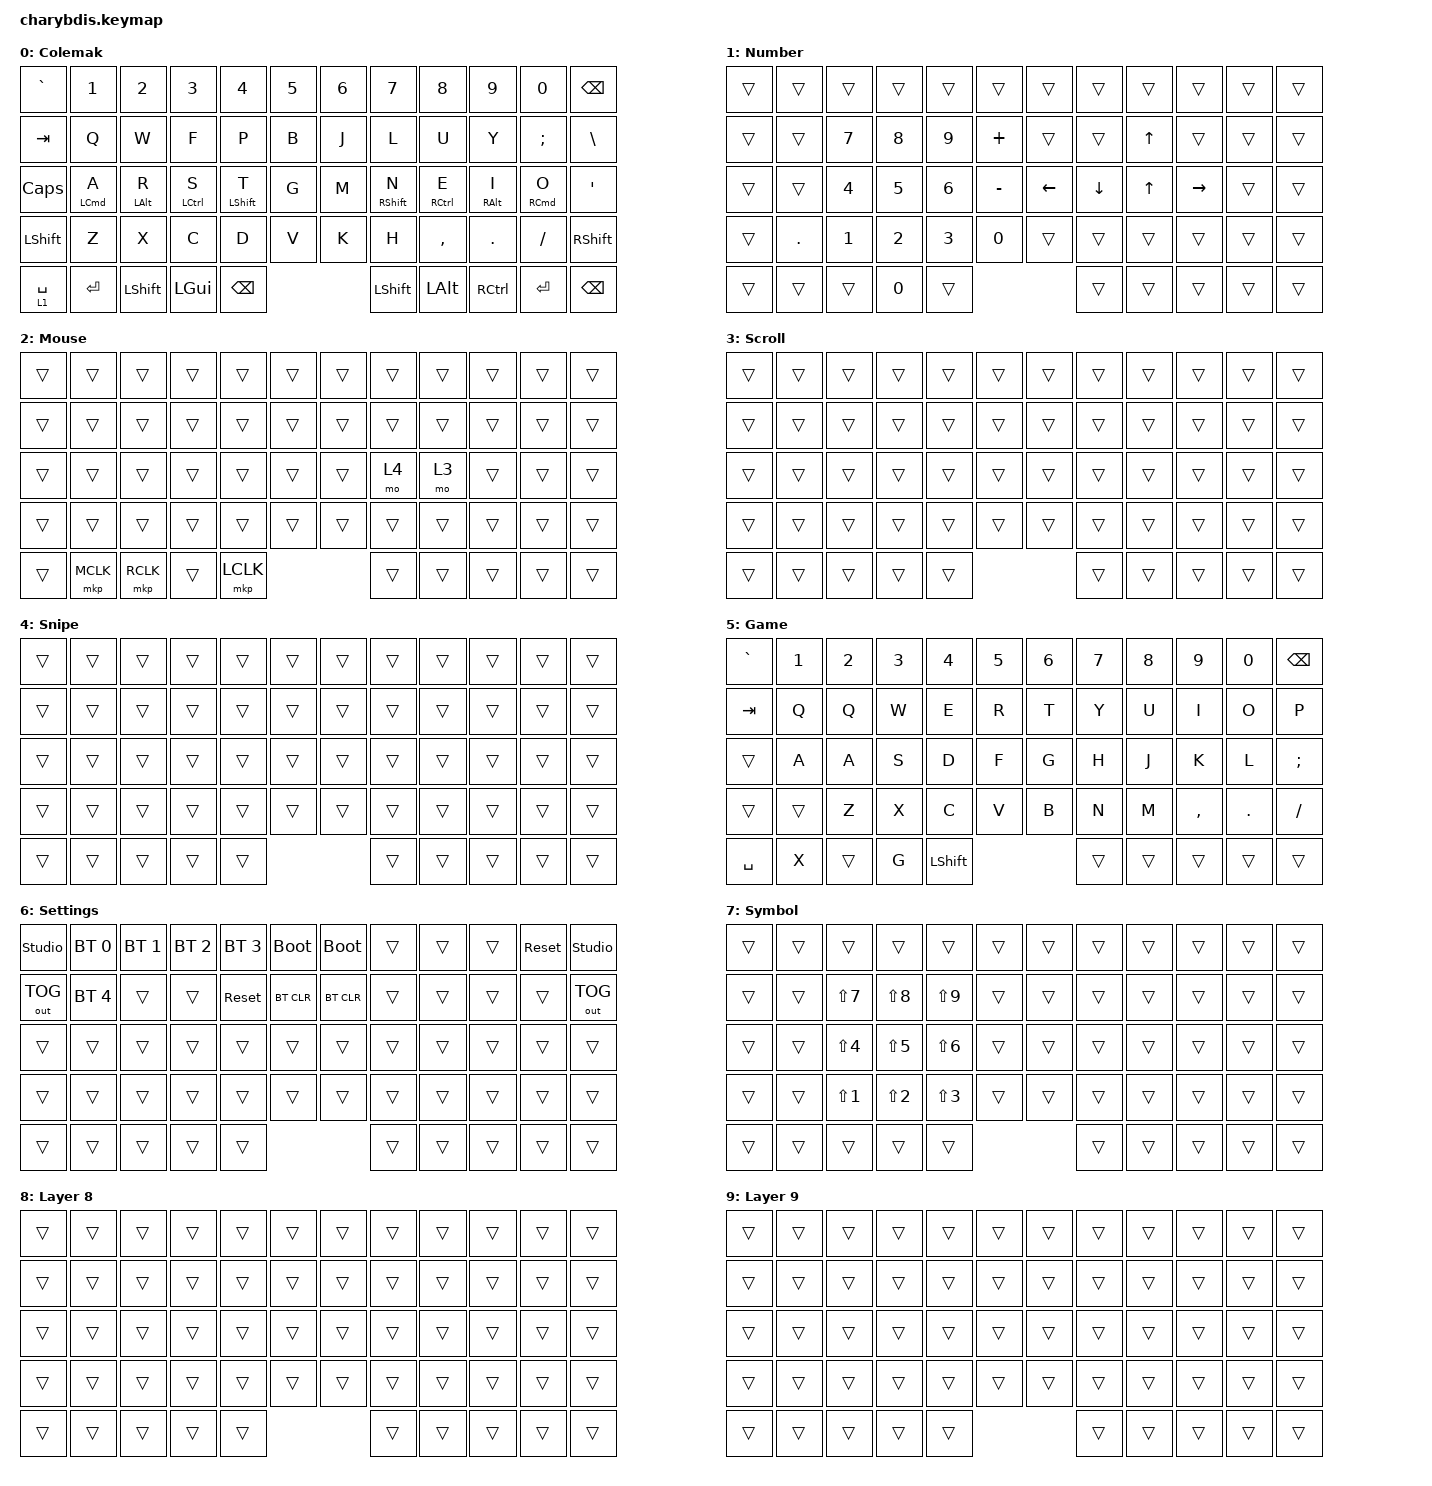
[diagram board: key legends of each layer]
#ifndef ZMK_BEHAVIORS_KEEP_ALL
#define ZMK_BEHAVIORS_KEEP_ALL
#endif
#include <behaviors.dtsi>
#include <behaviors/runtime_macro.dtsi>
#include <dt-bindings/zmk/bt.h>
#include <dt-bindings/zmk/ext_power.h>
#include <dt-bindings/zmk/keys.h>
#include <dt-bindings/zmk/outputs.h>
#include <dt-bindings/zmk/pointing.h>
#include <dt-bindings/input/input-event-codes.h>

/ {
    behaviors {
        hml: homewrow_mods_left {
            compatible = "zmk,behavior-hold-tap";
            bindings = <&kp>, <&kp>;

            #binding-cells = <2>;
            hold-trigger-key-positions = <6 7 8 9 10 11 18 19 20 21 22 23 30 31 32 33 34 35 42 43 44 45 46 47 53 54 55 56 57>;
            tapping-term-ms = <300>;
            flavor = "balanced";
            quick-tap-ms = <175>;
            require-prior-idle-ms = <250>;
            hold-trigger-on-release;
        };

        hmr: hmr {
            compatible = "zmk,behavior-hold-tap";
            bindings = <&kp>, <&kp>;

            #binding-cells = <2>;
            tapping-term-ms = <300>;
            hold-trigger-key-positions = <0 1 12 13 14 15 16 17 24 25 26 27 28 29 36 37 38 39 40 41 48 49 50 51 52 2 3 4 5>;
            flavor = "balanced";
            quick-tap-ms = <175>;
            require-prior-idle-ms = <250>;
            hold-trigger-on-release;
        };

        tap_preferred: tap_preferred {
            compatible = "zmk,behavior-hold-tap";
            bindings = <&mo>, <&kp>;

            #binding-cells = <2>;
            tapping-term-ms = <40>;
            flavor = "tap-preferred";
        };
    };

    combos {
        compatible = "zmk,combos";

        minus {
            bindings = <&kp MINUS>;
            key-positions = <30 31>;
        };

        par {
            bindings = <&kp RIGHT_PARENTHESIS>;
            key-positions = <31 32>;
        };

        par2 {
            bindings = <&kp LEFT_PARENTHESIS>;
            key-positions = <27 28>;
        };

        underscore {
            bindings = <&kp UNDER>;
            key-positions = <42 43>;
        };

        bra {
            bindings = <&kp LEFT_BRACKET>;
            key-positions = <27 26>;
        };

        right {
            bindings = <&kp RIGHT_BRACKET>;
            key-positions = <32 33>;
        };

        equal {
            bindings = <&kp EQUAL>;
            key-positions = <40 41>;
        };

        backspace {
            bindings = <&kp BACKSPACE>;
            key-positions = <39 40>;
        };

        delete {
            bindings = <&kp DELETE>;
            key-positions = <39 38>;
        };
    };

    keymap {
        compatible = "zmk,keymap";

        colemak_dh {
            display-name = "Colemak";
            bindings = <
&kp GRAVE    &kp N1       &kp N2           &kp N3        &kp N4             &kp N5      &kp N6  &kp N7              &kp N8        &kp N9            &kp N0       &kp BSPC
&kp TAB      &kp Q        &kp W            &kp F         &kp P              &kp B       &kp J   &kp L               &kp U         &kp Y             &kp SEMI     &kp BSLH
&kp CAPS     &hml LCMD A  &hml LEFT_ALT R  &hml LCTRL S  &hml LEFT_SHIFT T  &kp G       &kp M   &hmr RIGHT_SHIFT N  &hmr RCTRL E  &hmr RIGHT_ALT I  &hmr RCMD O  &kp APOS
&kp LSHFT    &kp Z        &kp X            &kp C         &kp D              &kp V       &kp K   &kp H               &kp COMMA     &kp DOT           &kp FSLH     &kp RSHFT
&lt 1 SPACE  &kp ENTER    &kp LSHFT        &kp LGUI      &kp BSPC                               &kp LSHFT           &kp LALT      &kp RCTRL         &kp ENTER    &kp BSPC
            >;
        };

        number {
            display-name = "Number";
            bindings = <
&trans  &trans   &trans  &trans  &trans  &trans       &trans    &trans    &trans        &trans     &trans  &trans
&trans  &trans   &kp N7  &kp N8  &kp N9  &kp PLUS     &trans    &trans    &kp UP        &trans     &trans  &trans
&trans  &trans   &kp N4  &kp N5  &kp N6  &kp MINUS    &kp LEFT  &kp DOWN  &kp UP_ARROW  &kp RIGHT  &trans  &trans
&trans  &kp DOT  &kp N1  &kp N2  &kp N3  &kp N0       &trans    &trans    &trans        &trans     &trans  &trans
&trans  &trans   &trans  &kp N0  &trans                         &trans    &trans        &trans     &trans  &trans
            >;
        };

        auto_mouse {
            display-name = "Mouse";
            bindings = <
&trans  &trans     &trans     &trans  &trans     &trans    &trans  &trans  &trans  &trans  &trans  &trans
&trans  &trans     &trans     &trans  &trans     &trans    &trans  &trans  &trans  &trans  &trans  &trans
&trans  &trans     &trans     &trans  &trans     &trans    &trans  &mo 4   &mo 3   &trans  &trans  &trans
&trans  &trans     &trans     &trans  &trans     &trans    &trans  &trans  &trans  &trans  &trans  &trans
&trans  &mkp MCLK  &mkp RCLK  &trans  &mkp LCLK                    &trans  &trans  &trans  &trans  &trans
            >;
        };

        scroll {
            display-name = "Scroll";
            bindings = <
&trans  &trans  &trans  &trans  &trans  &trans    &trans  &trans  &trans  &trans  &trans  &trans
&trans  &trans  &trans  &trans  &trans  &trans    &trans  &trans  &trans  &trans  &trans  &trans
&trans  &trans  &trans  &trans  &trans  &trans    &trans  &trans  &trans  &trans  &trans  &trans
&trans  &trans  &trans  &trans  &trans  &trans    &trans  &trans  &trans  &trans  &trans  &trans
&trans  &trans  &trans  &trans  &trans                    &trans  &trans  &trans  &trans  &trans
            >;
        };

        snipe_layer {
            display-name = "Snipe";
            bindings = <
&trans  &trans  &trans  &trans  &trans  &trans    &trans  &trans  &trans  &trans  &trans  &trans
&trans  &trans  &trans  &trans  &trans  &trans    &trans  &trans  &trans  &trans  &trans  &trans
&trans  &trans  &trans  &trans  &trans  &trans    &trans  &trans  &trans  &trans  &trans  &trans
&trans  &trans  &trans  &trans  &trans  &trans    &trans  &trans  &trans  &trans  &trans  &trans
&trans  &trans  &trans  &trans  &trans                    &trans  &trans  &trans  &trans  &trans
            >;
        };

        game {
            display-name = "Game";
            bindings = <
&kp GRAVE  &kp N1  &kp N2  &kp N3  &kp N4     &kp N5    &kp N6  &kp N7  &kp N8  &kp N9     &kp N0   &kp BSPC
&kp TAB    &kp Q   &kp Q   &kp W   &kp E      &kp R     &kp T   &kp Y   &kp U   &kp I      &kp O    &kp P
&trans     &kp A   &kp A   &kp S   &kp D      &kp F     &kp G   &kp H   &kp J   &kp K      &kp L    &kp SEMI
&trans     &trans  &kp Z   &kp X   &kp C      &kp V     &kp B   &kp N   &kp M   &kp COMMA  &kp DOT  &kp FSLH
&kp SPACE  &kp X   &trans  &kp G   &kp LSHFT                    &trans  &trans  &trans     &trans   &trans
            >;
        };

        settings {
            display-name = "Settings";
            bindings = <
&studio_unlock  &bt BT_SEL 0  &bt BT_SEL 1  &bt BT_SEL 2  &bt BT_SEL 3  &bootloader    &bootloader  &trans  &trans  &trans  &sys_reset  &studio_unlock
&out OUT_TOG    &bt BT_SEL 4  &trans        &trans        &sys_reset    &bt BT_CLR     &bt BT_CLR   &trans  &trans  &trans  &trans      &out OUT_TOG
&trans          &trans        &trans        &trans        &trans        &trans         &trans       &trans  &trans  &trans  &trans      &trans
&trans          &trans        &trans        &trans        &trans        &trans         &trans       &trans  &trans  &trans  &trans      &trans
&trans          &trans        &trans        &trans        &trans                                    &trans  &trans  &trans  &trans      &trans
            >;
        };

        symbol {
            display-name = "Symbol";
            bindings = <
&trans  &trans  &trans      &trans      &trans      &trans    &trans  &trans  &trans  &trans  &trans  &trans
&trans  &trans  &kp LS(N7)  &kp LS(N8)  &kp LS(N9)  &trans    &trans  &trans  &trans  &trans  &trans  &trans
&trans  &trans  &kp LS(N4)  &kp LS(N5)  &kp LS(N6)  &trans    &trans  &trans  &trans  &trans  &trans  &trans
&trans  &trans  &kp LS(N1)  &kp LS(N2)  &kp LS(N3)  &trans    &trans  &trans  &trans  &trans  &trans  &trans
&trans  &trans  &trans      &trans      &trans                        &trans  &trans  &trans  &trans  &trans
            >;
        };

        layer_8 {
            display-name = "Layer 8";
            bindings = <
&trans  &trans  &trans  &trans  &trans  &trans    &trans  &trans  &trans  &trans  &trans  &trans
&trans  &trans  &trans  &trans  &trans  &trans    &trans  &trans  &trans  &trans  &trans  &trans
&trans  &trans  &trans  &trans  &trans  &trans    &trans  &trans  &trans  &trans  &trans  &trans
&trans  &trans  &trans  &trans  &trans  &trans    &trans  &trans  &trans  &trans  &trans  &trans
&trans  &trans  &trans  &trans  &trans                    &trans  &trans  &trans  &trans  &trans
            >;
        };

        layer_9 {
            display-name = "Layer 9";
            bindings = <
&trans  &trans  &trans  &trans  &trans  &trans    &trans  &trans  &trans  &trans  &trans  &trans
&trans  &trans  &trans  &trans  &trans  &trans    &trans  &trans  &trans  &trans  &trans  &trans
&trans  &trans  &trans  &trans  &trans  &trans    &trans  &trans  &trans  &trans  &trans  &trans
&trans  &trans  &trans  &trans  &trans  &trans    &trans  &trans  &trans  &trans  &trans  &trans
&trans  &trans  &trans  &trans  &trans                    &trans  &trans  &trans  &trans  &trans
            >;
        };
    };
};

// ---------------------------------------------------------------------------
// Trackball runtime input processors (DYA Studio "Trackball" tab)
// ---------------------------------------------------------------------------

&mouse_runtime_input_processor {
    temp-layer-enabled;
    temp-layer = <2>;
    temp-layer-activation-delay-ms = <100>;
    temp-layer-deactivation-delay-ms = <1000>;
};

&scroll_runtime_input_processor {
    active-layers = <BIT(3)>;
    x-codes = <INPUT_REL_X>;
    y-codes = <INPUT_REL_Y>;
    xy-to-scroll-enabled;
    y-invert;
    scale-multiplier = <1>;
    scale-divisor = <10>;
    axis-snap-threshold = <100>;
};

